# G32F031 register map
File version: 1.0
CPU: CM0PLUS r0p1, little endian, no MPU, no FPU, 2 interrupt priority bits
Registers are 32-bit, read-write, reset 0x0 unless marked. A register's access mark holds for its fields unless they carry their own. Offsets are from the block's base; [hi:lo] are bit positions; {n}, {i} and the like mark numbered series; 'fields as' and 'values as' point back to an identical list.

## COMP1 — Comparator
Base 0x40006000
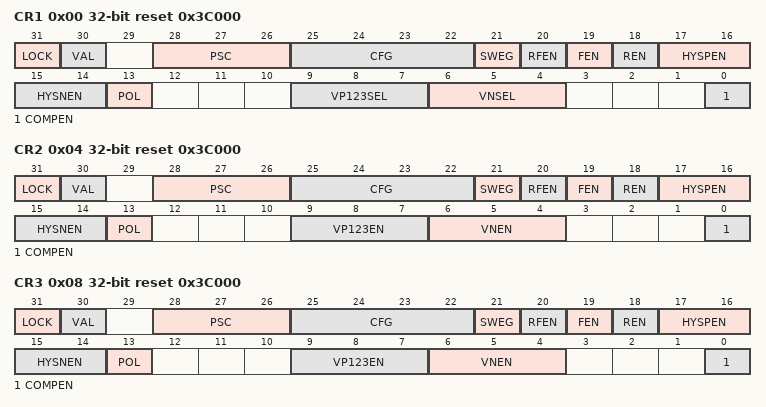
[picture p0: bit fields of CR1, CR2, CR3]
0x00 CR1 access per field reset 0x3C000 — Control Register 1
  [31] LOCK rw
  [30] VAL ro — Comparator outputs the level value before polarity selector and shielding.
  [28:26] PSC rw — Digital filter fractional division configuration
  [25:22] CFG rw — Digital filter fractional clock configuration
  [21] SWEG rw — soft interrupt
  [20] RFEN rw — Comparator interrupt rising and falling edge enable
  [19] FEN rw — Comparator interrupt falling edge enable
  [18] REN rw — Comparator interrupt rising edge enable
  [17:16] HYSPEN rw — Delay function enabled
  [15:14] HYSNEN rw — Delay function enabled
  [13] POL rw — The output polarity of comparator .
  [9:7] VP123SEL rw — Comparator positive input voltage selection
  [6:4] VNSEL rw — Comparator negative input voltage selection
  [0] COMPEN rw — Module enablement
0x04 CR2 access per field reset 0x3C000 — Control Register 2
  [31] LOCK rw
  [30] VAL ro — Comparator outputs the level value before polarity selector and shielding.
  [28:26] PSC rw — Digital filter fractional division configuration
  [25:22] CFG rw — Digital filter fractional clock configuration
  [21] SWEG rw — soft interrupt
  [20] RFEN rw — Comparator interrupt rising and falling edge enable
  [19] FEN rw — Comparator interrupt falling edge enable
  [18] REN rw — Comparator interrupt rising edge enable
  [17:16] HYSPEN rw — Delay function enabled
  [15:14] HYSNEN rw — Delay function enabled
  [13] POL rw — The output polarity of comparator .
  [9:7] VP123EN rw — Comparator positive input voltage selection
  [6:4] VNEN rw — Comparator negative input voltage selection
  [0] COMPEN rw — Module enablement
0x08 CR3 access per field reset 0x3C000 — Control Register 3
  fields as CR2
{0x8+4i} ISR{i} (i=1..3) — Status register
  [0] IFLG — interrupt flag

## DMA — DMA controller
Base 0x40020000
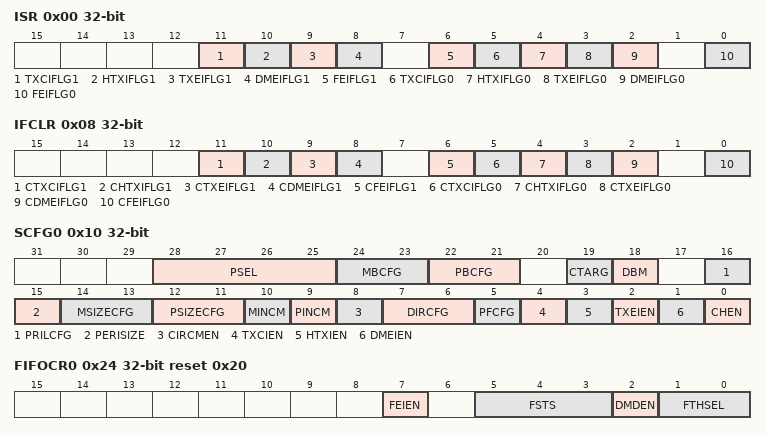
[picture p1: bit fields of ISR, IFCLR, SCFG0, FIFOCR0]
0x00 ISR ro — Interrupt Status Register
  [11] TXCIFLG1 — Stream 1 transfer complete interrupt flag
  [10] HTXIFLG1 — Stream 1 half transfer interrupt flag
  [9] TXEIFLG1 — Stream 1 transfer error interrupt flag
  [8] DMEIFLG1 — Stream 1 direct mode error interrupt flag
  [6] FEIFLG1 — Stream 1 FIFO error interrupt flag
  [5] TXCIFLG0 — Stream 0 transfer complete interrupt flag
  [4] HTXIFLG0 — Stream 0 half transfer interrupt flag
  [3] TXEIFLG0 — Stream 0 transfer error interrupt flag
  [2] DMEIFLG0 — Stream 0 direct mode error interrupt flag
  [0] FEIFLG0 — Stream 0 FIFO error interrupt flag
0x08 IFCLR — Interrupt Flag Clear Register
  [11] CTXCIFLG1 — Stream 1 clear transfer complete interrupt flag
  [10] CHTXIFLG1 — Stream 1 clear half transfer interrupt flag
  [9] CTXEIFLG1 — Stream 1 clear transfer error interrupt flag
  [8] CDMEIFLG1 — Stream 1 clear direct mode error interrupt flag
  [6] CFEIFLG1 — Stream 1 clear FIFO error interrupt flag
  [5] CTXCIFLG0 — Stream 0 clear transfer complete interrupt flag
  [4] CHTXIFLG0 — Stream 0 clear half transfer interrupt flag
  [3] CTXEIFLG0 — Stream 0 clear transfer error interrupt flag
  [2] CDMEIFLG0 — Stream 0 clear direct mode error interrupt flag
  [0] CFEIFLG0 — Stream 0 clear FIFO error interrupt flag
0x10 SCFG0
  [28:25] PSEL — Channel selection
  [24:23] MBCFG — Memory burst transfer configuration
  [22:21] PBCFG — Peripheral burst transfer configuration
  [19] CTARG — Current target (only in double buffer mode)
  [18] DBM — Double buffer mode
  [16] PRILCFG — Priority level
  [15] PERISIZE — Peripheral increment offset size
  [14:13] MSIZECFG — Memory data size
  [12:11] PSIZECFG — Peripheral data size
  [10] MINCM — Memory increment mode
  [9] PINCM — Peripheral increment mode
  [8] CIRCMEN — Circular mode
  [7:6] DIRCFG — Data transfer direction
  [5] PFCFG — Peripheral flow controller
  [4] TXCIEN — Transfer complete interrupt enable
  [3] HTXIEN — Half transfer interrupt enable
  [2] TXEIEN — Transfer error interrupt enable
  [1] DMEIEN — Direct mode error interrupt enable
  [0] CHEN — Stream enable / flag stream ready when read low
0x14 NDATA0
  [15:0] NDATA — Number of data items to transfer
0x18 PADDR0
  [31:0] PADDR — Peripheral address
0x1C M0ADDR0
  [31:0] M0ADDR — Memory 0 address
0x20 M1ADDR0
  [31:0] M1ADDR — Memory 1 address (used in case of Double buffer mode)
0x24 FIFOCR0 access per field reset 0x20
  [7] FEIEN rw — FIFO error interrupt enable
  [5:3] FSTS ro — FIFO status
  [2] DMDEN rw — Direct mode disable
  [1:0] FTHSEL rw — FIFO threshold selection
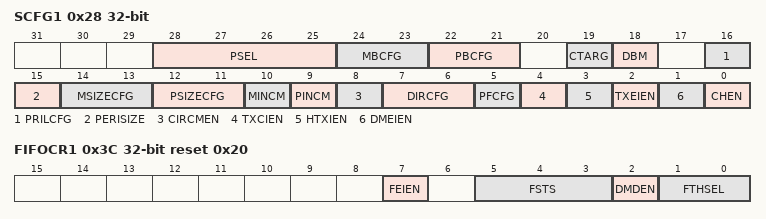
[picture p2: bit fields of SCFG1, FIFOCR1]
0x28 SCFG1
  fields as SCFG0
0x2C NDATA1
  [15:0] NDATA — Number of data items to transfer
0x30 PADDR1
  [31:0] PADDR — Peripheral address
0x34 M0ADDR1 reset 0xFFF0000
  [31:0] M0ADDR — Memory 0 address
0x38 M1ADDR1
  fields as M1ADDR0
0x3C FIFOCR1 access per field reset 0x20
  fields as FIFOCR0
